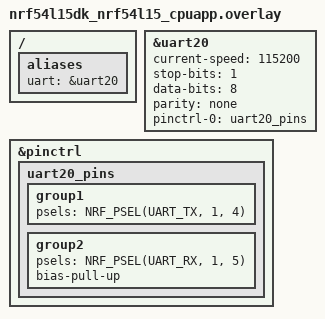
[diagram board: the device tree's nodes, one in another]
/ {
    aliases {
        uart = &uart20;
    };  
};

/*configure the uart 20, 115200 bauds, 8N1*/
&uart20 {
    status = "okay";
    current-speed = <115200>;
    stop-bits = "1";
    data-bits = <8>;
    parity = "none";
	pinctrl-0 = <&uart20_pins>;
	pinctrl-names = "default", "sleep";
};

/*configure uart pins as Tx and Rx pins*/
&pinctrl {
	uart20_pins: uart20_pins {
		group1 {
			psels = <NRF_PSEL(UART_TX, 1, 4)>;
		};

        group2 {
			psels = <NRF_PSEL(UART_RX, 1, 5)>;
			bias-pull-up;
		};
    };
};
